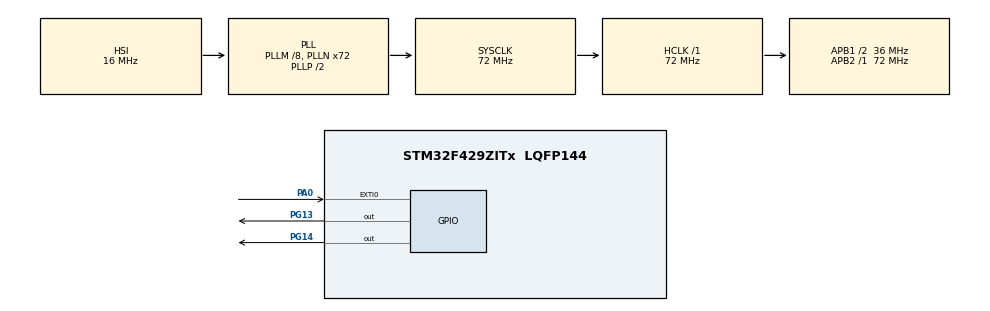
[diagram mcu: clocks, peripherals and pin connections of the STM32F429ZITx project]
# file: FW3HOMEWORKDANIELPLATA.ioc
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FREERTOS.Tasks01=defaultTask,0,4096,StartDefaultTask,Default,NULL,Dynamic,NULL,NULL
FREERTOS.configCHECK_FOR_STACK_OVERFLOW=2
FREERTOS.configTOTAL_HEAP_SIZE=32768
FREERTOS.configUSE_APPLICATION_TASK_TAG=1
FREERTOS.configUSE_COUNTING_SEMAPHORES=1
FREERTOS.configUSE_IDLE_HOOK=1
FREERTOS.configUSE_MALLOC_FAILED_HOOK=1
FREERTOS.configUSE_RECURSIVE_MUTEXES=1
Mcu.Family=STM32F4
Mcu.Name=STM32F429ZITx
Mcu.Package=LQFP144
NVIC.DMA2D_IRQn=true\:5\:0\:true\:false\:true\:true\:true\:true\:true
NVIC.EXTI0_IRQn=true\:5\:0\:false\:false\:true\:true\:true\:true\:true
NVIC.PriorityGroup=NVIC_PRIORITYGROUP_4
PA0/WKUP.Signal=GPXTI0
PA13.Mode=Serial_Wire
PA13.Signal=SYS_JTMS-SWDIO
PA14.Mode=Serial_Wire
PA14.Signal=SYS_JTCK-SWCLK
PG13.GPIO_Mode=GPIO_MODE_OUTPUT_PP
PG13.GPIO_PuPd=GPIO_NOPULL
PG13.GPIO_Speed=GPIO_SPEED_FREQ_LOW
PG13.Signal=GPIO_Output
PG14.Signal=GPIO_Output
ProjectManager.HeapSize=0x200
ProjectManager.StackSize=0x400
ProjectManager.TargetToolchain=STM32CubeIDE
RCC.48MHZClocksFreq_Value=48000000
RCC.AHBFreq_Value=72000000
RCC.APB1CLKDivider=RCC_HCLK_DIV2
RCC.APB1Freq_Value=36000000
RCC.APB1TimFreq_Value=72000000
RCC.APB2Freq_Value=72000000
RCC.APB2TimFreq_Value=72000000
RCC.CortexFreq_Value=72000000
RCC.HCLKFreq_Value=72000000
RCC.HSE_VALUE=8000000
RCC.HSI_VALUE=16000000
RCC.LSE_VALUE=32768
RCC.PLLM=8
RCC.PLLN=72
RCC.PLLQ=3
RCC.PLLSAIN=50
RCC.SYSCLKFreq_VALUE=72000000
RCC.SYSCLKSource=RCC_SYSCLKSOURCE_PLLCLK
RCC.VCOOutputFreq_Value=144000000
VP_CRC_VS_CRC.Mode=CRC_Activate
VP_DMA2D_VS_DMA2D.Mode=DMA2D_Activate
VP_FREERTOS_VS_CMSIS_V1.Mode=CMSIS_V1
VP_TIM1_VS_ClockSourceINT.Mode=Internal
board=STM32F429I-DISC1

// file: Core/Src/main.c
/* USER CODE BEGIN Header */
/**
  ******************************************************************************
  * @file           : main.c
  * @brief          : Main program body
  ******************************************************************************
  * @attention
  *
  * Copyright (c) 2023 STMicroelectronics.
  * All rights reserved.
  *
  * This software is licensed under terms that can be found in the LICENSE file
  * in the root directory of this software component.
  * If no LICENSE file comes with this software, it is provided AS-IS.
  *
  ******************************************************************************
  */
/* USER CODE END Header */
#include "main.h"
#include "cmsis_os.h"

CRC_HandleTypeDef hcrc;

DMA2D_HandleTypeDef hdma2d;

TIM_HandleTypeDef htim1;

osThreadId defaultTaskHandle;
/* USER CODE BEGIN PV */
uint8_t semaforo=1;
/* USER CODE END PV */

void SystemClock_Config(void);
static void MX_GPIO_Init(void);
static void MX_CRC_Init(void);
static void MX_DMA2D_Init(void);
static void MX_TIM1_Init(void);
void StartDefaultTask(void const * argument);

int main(void)
{

  /* MCU Configuration--------------------------------------------------------*/

  /* Reset of all peripherals, Initializes the Flash interface and the Systick. */
  HAL_Init();

  /* Configure the system clock */
  SystemClock_Config();

  /* Initialize all configured peripherals */
  MX_GPIO_Init();
  MX_CRC_Init();
  MX_DMA2D_Init();
  MX_TIM1_Init();

  /* Create the thread(s) */
  /* definition and creation of defaultTask */
  osThreadDef(defaultTask, StartDefaultTask, osPriorityNormal, 0, 4096);
  defaultTaskHandle = osThreadCreate(osThread(defaultTask), NULL);

  /* Start scheduler */
  osKernelStart();

  /* We should never get here as control is now taken by the scheduler */
  /* Infinite loop */
  while (1)
  {
	  if (semaforo==0){
		  HAL_GPIO_WritePin(GPIOG, GPIO_PIN_13, GPIO_PIN_RESET);
		  HAL_GPIO_WritePin(GPIOG, GPIO_PIN_14, GPIO_PIN_RESET);
	  } else{
		  HAL_GPIO_TogglePin(GPIOG, GPIO_PIN_13);
		  HAL_GPIO_TogglePin(GPIOG, GPIO_PIN_14);
		  HAL_Delay(1000*semaforo);

	}
  }
}

void SystemClock_Config(void)
{
  RCC_OscInitTypeDef RCC_OscInitStruct = {0};
  RCC_ClkInitTypeDef RCC_ClkInitStruct = {0};

  /** Configure the main internal regulator output voltage
  */
  __HAL_RCC_PWR_CLK_ENABLE();
  __HAL_PWR_VOLTAGESCALING_CONFIG(PWR_REGULATOR_VOLTAGE_SCALE3);

  /** Initializes the RCC Oscillators according to the specified parameters
  * in the RCC_OscInitTypeDef structure.
  */
  RCC_OscInitStruct.OscillatorType = RCC_OSCILLATORTYPE_HSI;
  RCC_OscInitStruct.HSIState = RCC_HSI_ON;
  RCC_OscInitStruct.HSICalibrationValue = RCC_HSICALIBRATION_DEFAULT;
  RCC_OscInitStruct.PLL.PLLState = RCC_PLL_ON;
  RCC_OscInitStruct.PLL.PLLSource = RCC_PLLSOURCE_HSI;
  RCC_OscInitStruct.PLL.PLLM = 8;
  RCC_OscInitStruct.PLL.PLLN = 72;
  RCC_OscInitStruct.PLL.PLLP = RCC_PLLP_DIV2;
  RCC_OscInitStruct.PLL.PLLQ = 3;
  if (HAL_RCC_OscConfig(&RCC_OscInitStruct) != HAL_OK)
  {
    Error_Handler();
  }

  /** Initializes the CPU, AHB and APB buses clocks
  */
  RCC_ClkInitStruct.ClockType = RCC_CLOCKTYPE_HCLK|RCC_CLOCKTYPE_SYSCLK
                              |RCC_CLOCKTYPE_PCLK1|RCC_CLOCKTYPE_PCLK2;
  RCC_ClkInitStruct.SYSCLKSource = RCC_SYSCLKSOURCE_PLLCLK;
  RCC_ClkInitStruct.AHBCLKDivider = RCC_SYSCLK_DIV1;
  RCC_ClkInitStruct.APB1CLKDivider = RCC_HCLK_DIV2;
  RCC_ClkInitStruct.APB2CLKDivider = RCC_HCLK_DIV1;

  if (HAL_RCC_ClockConfig(&RCC_ClkInitStruct, FLASH_LATENCY_2) != HAL_OK)
  {
    Error_Handler();
  }
}

static void MX_CRC_Init(void)
{

  hcrc.Instance = CRC;
  if (HAL_CRC_Init(&hcrc) != HAL_OK)
  {
    Error_Handler();
  }

}

static void MX_DMA2D_Init(void)
{

  hdma2d.Instance = DMA2D;
  hdma2d.Init.Mode = DMA2D_M2M;
  hdma2d.Init.ColorMode = DMA2D_OUTPUT_ARGB8888;
  hdma2d.Init.OutputOffset = 0;
  hdma2d.LayerCfg[1].InputOffset = 0;
  hdma2d.LayerCfg[1].InputColorMode = DMA2D_INPUT_ARGB8888;
  hdma2d.LayerCfg[1].AlphaMode = DMA2D_NO_MODIF_ALPHA;
  hdma2d.LayerCfg[1].InputAlpha = 0;
  if (HAL_DMA2D_Init(&hdma2d) != HAL_OK)
  {
    Error_Handler();
  }
  if (HAL_DMA2D_ConfigLayer(&hdma2d, 1) != HAL_OK)
  {
    Error_Handler();
  }

}

static void MX_TIM1_Init(void)
{

  TIM_ClockConfigTypeDef sClockSourceConfig = {0};
  TIM_MasterConfigTypeDef sMasterConfig = {0};

  htim1.Instance = TIM1;
  htim1.Init.Prescaler = 0;
  htim1.Init.CounterMode = TIM_COUNTERMODE_UP;
  htim1.Init.Period = 65535;
  htim1.Init.ClockDivision = TIM_CLOCKDIVISION_DIV1;
  htim1.Init.RepetitionCounter = 0;
  htim1.Init.AutoReloadPreload = TIM_AUTORELOAD_PRELOAD_DISABLE;
  if (HAL_TIM_Base_Init(&htim1) != HAL_OK)
  {
    Error_Handler();
  }
  sClockSourceConfig.ClockSource = TIM_CLOCKSOURCE_INTERNAL;
  if (HAL_TIM_ConfigClockSource(&htim1, &sClockSourceConfig) != HAL_OK)
  {
    Error_Handler();
  }
  sMasterConfig.MasterOutputTrigger = TIM_TRGO_RESET;
  sMasterConfig.MasterSlaveMode = TIM_MASTERSLAVEMODE_DISABLE;
  if (HAL_TIMEx_MasterConfigSynchronization(&htim1, &sMasterConfig) != HAL_OK)
  {
    Error_Handler();
  }

}

static void MX_GPIO_Init(void)
{
  GPIO_InitTypeDef GPIO_InitStruct = {0};

  /* GPIO Ports Clock Enable */
  __HAL_RCC_GPIOA_CLK_ENABLE();
  __HAL_RCC_GPIOG_CLK_ENABLE();

  /*Configure GPIO pin Output Level */
  HAL_GPIO_WritePin(GPIOG, GPIO_PIN_13|GPIO_PIN_14, GPIO_PIN_RESET);

  /*Configure GPIO pin : PA0 */
  GPIO_InitStruct.Pin = GPIO_PIN_0;
  GPIO_InitStruct.Mode = GPIO_MODE_IT_RISING;
  GPIO_InitStruct.Pull = GPIO_NOPULL;
  HAL_GPIO_Init(GPIOA, &GPIO_InitStruct);

  /*Configure GPIO pins : PG13 PG14 */
  GPIO_InitStruct.Pin = GPIO_PIN_13|GPIO_PIN_14;
  GPIO_InitStruct.Mode = GPIO_MODE_OUTPUT_PP;
  GPIO_InitStruct.Pull = GPIO_NOPULL;
  GPIO_InitStruct.Speed = GPIO_SPEED_FREQ_LOW;
  HAL_GPIO_Init(GPIOG, &GPIO_InitStruct);

  /* EXTI interrupt init*/
  HAL_NVIC_SetPriority(EXTI0_IRQn, 5, 0);
  HAL_NVIC_EnableIRQ(EXTI0_IRQn);

}

/* USER CODE BEGIN 4 */
void HAL_GPIO_EXTI_Callback(uint16_t GPIO_Pin)
{
  /* Prevent unused argument(s) compilation warning */

	if (semaforo==0){
		semaforo=1;
	} else if (semaforo==1){
		semaforo=2;
	} else if (semaforo==2){
		semaforo=3;
	} else if (semaforo==3){
		semaforo=0;
	}

  /* NOTE: This function Should not be modified, when the callback is needed,
           the HAL_GPIO_EXTI_Callback could be implemented in the user file
   */
}
/* USER CODE END 4 */

void StartDefaultTask(void const * argument)
{
  for(;;)
  {
    osDelay(1);
  }
}

void Error_Handler(void)
{
  __disable_irq();
  while (1)
  {
  }
}
